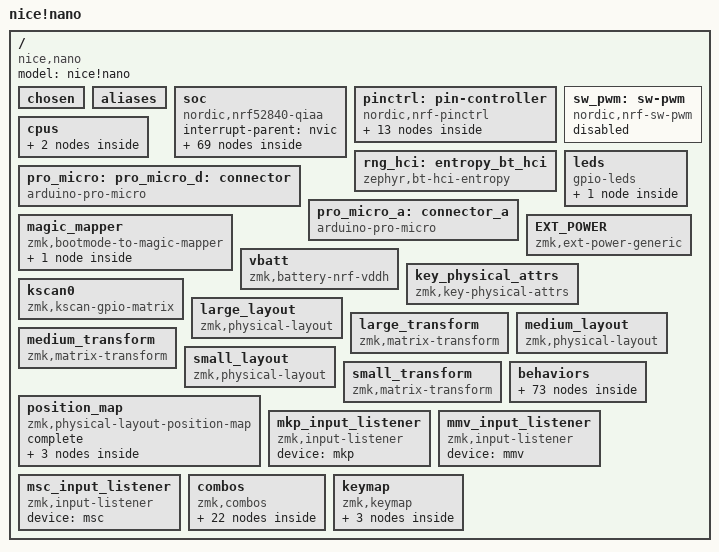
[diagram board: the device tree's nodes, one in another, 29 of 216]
/dts-v1/;

/ {
	#address-cells = < 0x1 >;
	#size-cells = < 0x1 >;
	model = "nice!nano";
	compatible = "nice,nano";
	chosen {
		zephyr,bt-hci = &bt_hci_controller;
		zephyr,entropy = &rng;
		zephyr,flash-controller = &flash_controller;
		zephyr,code-partition = &code_partition;
		zephyr,sram = &sram0;
		zephyr,flash = &flash0;
		zephyr,boot-mode = &boot_retention;
		zmk,magic-boot-mode = &adafruit_boot_retention;
		zmk,battery = &vbatt;
		zmk,kscan = &kscan0;
		zmk,physical-layout = &large_layout;
		zmk,studio-rpc-uart = &snippet_studio_rpc_usb_uart;
	};
	aliases {
	};
	soc {
		#address-cells = < 0x1 >;
		#size-cells = < 0x1 >;
		compatible = "nordic,nrf52840-qiaa", "nordic,nrf52840", "nordic,nrf52", "simple-bus";
		interrupt-parent = < &nvic >;
		ranges;
		nvic: interrupt-controller@e000e100 {
			#address-cells = < 0x1 >;
			compatible = "arm,v7m-nvic";
			reg = < 0xe000e100 0xc00 >;
			interrupt-controller;
			#interrupt-cells = < 0x2 >;
			arm,num-irq-priority-bits = < 0x3 >;
			phandle = < 0x1 >;
		};
		systick: timer@e000e010 {
			compatible = "arm,armv7m-systick";
			reg = < 0xe000e010 0x10 >;
			status = "disabled";
		};
		ficr: ficr@10000000 {
			compatible = "nordic,nrf-ficr";
			reg = < 0x10000000 0x1000 >;
			#nordic,ficr-cells = < 0x1 >;
			status = "okay";
		};
		uicr: uicr@10001000 {
			compatible = "nordic,nrf-uicr";
			reg = < 0x10001000 0x1000 >;
			status = "okay";
		};
		sram0: memory@20000000 {
			compatible = "mmio-sram";
			reg = < 0x20000000 0x40000 >;
		};
		clock: clock@40000000 {
			compatible = "nordic,nrf-clock";
			reg = < 0x40000000 0x1000 >;
			interrupts = < 0x0 0x1 >;
			status = "okay";
		};
		power: power@40000000 {
			compatible = "nordic,nrf-power";
			reg = < 0x40000000 0x1000 >;
			interrupts = < 0x0 0x1 >;
			status = "okay";
			#address-cells = < 0x1 >;
			#size-cells = < 0x1 >;
			gpregret1: gpregret1@4000051c {
				#address-cells = < 0x1 >;
				#size-cells = < 0x1 >;
				compatible = "nordic,nrf-gpregret";
				reg = < 0x4000051c 0x1 >;
				status = "okay";
				adafruit_boot_retention: retention@0 {
					compatible = "zephyr,retention";
					status = "okay";
					reg = < 0x0 0x1 >;
				};
			};
			gpregret2: gpregret2@40000520 {
				#address-cells = < 0x1 >;
				#size-cells = < 0x1 >;
				compatible = "nordic,nrf-gpregret";
				reg = < 0x40000520 0x1 >;
				status = "okay";
			};
			reg1: regulator@40000578 {
				compatible = "nordic,nrf5x-regulator";
				reg = < 0x40000578 0x1 >;
				regulator-name = "REG1";
				regulator-initial-mode = < 0x1 >;
			};
			reg0: regulator@40000580 {
				compatible = "nordic,nrf52x-regulator-hv";
				reg = < 0x40000580 0x1 >;
				regulator-name = "REG0";
				status = "okay";
			};
		};
		radio: radio@40001000 {
			compatible = "nordic,nrf-radio";
			reg = < 0x40001000 0x1000 >;
			interrupts = < 0x1 0x1 >;
			status = "okay";
			ieee802154-supported;
			ble-2mbps-supported;
			ble-coded-phy-supported;
			tx-high-power-supported;
			ieee802154: ieee802154 {
				compatible = "nordic,nrf-ieee802154";
				status = "disabled";
			};
			bt_hci_controller: bt_hci_controller {
				compatible = "zephyr,bt-hci-ll-sw-split";
				status = "okay";
			};
		};
		uart0: pro_micro_serial: uart@40002000 {
			compatible = "nordic,nrf-uarte";
			reg = < 0x40002000 0x1000 >;
			interrupts = < 0x2 0x1 >;
			status = "disabled";
			current-speed = < 0x1c200 >;
			pinctrl-0 = < &uart0_default >;
			pinctrl-1 = < &uart0_sleep >;
			pinctrl-names = "default", "sleep";
		};
		i2c0: pro_micro_i2c: i2c@40003000 {
			compatible = "nordic,nrf-twi";
			#address-cells = < 0x1 >;
			#size-cells = < 0x0 >;
			reg = < 0x40003000 0x1000 >;
			interrupts = < 0x3 0x1 >;
			easydma-maxcnt-bits = < 0x10 >;
			status = "disabled";
			zephyr,pm-device-runtime-auto;
			pinctrl-0 = < &i2c0_default >;
			pinctrl-1 = < &i2c0_sleep >;
			pinctrl-names = "default", "sleep";
		};
		spi0: spi@40003000 {
			compatible = "nordic,nrf-spim";
			#address-cells = < 0x1 >;
			#size-cells = < 0x0 >;
			reg = < 0x40003000 0x1000 >;
			interrupts = < 0x3 0x1 >;
			max-frequency = < 0x7a1200 >;
			easydma-maxcnt-bits = < 0x10 >;
			status = "disabled";
		};
		i2c1: i2c@40004000 {
			compatible = "nordic,nrf-twim";
			#address-cells = < 0x1 >;
			#size-cells = < 0x0 >;
			reg = < 0x40004000 0x1000 >;
			interrupts = < 0x4 0x1 >;
			easydma-maxcnt-bits = < 0x10 >;
			status = "disabled";
			zephyr,pm-device-runtime-auto;
		};
		spi1: pro_micro_spi: spi@40004000 {
			compatible = "nordic,nrf-spim";
			#address-cells = < 0x1 >;
			#size-cells = < 0x0 >;
			reg = < 0x40004000 0x1000 >;
			interrupts = < 0x4 0x1 >;
			max-frequency = < 0x7a1200 >;
			easydma-maxcnt-bits = < 0x10 >;
			status = "disabled";
			pinctrl-0 = < &spi1_default >;
			pinctrl-1 = < &spi1_sleep >;
			pinctrl-names = "default", "sleep";
		};
		nfct: nfct@40005000 {
			compatible = "nordic,nrf-nfct";
			reg = < 0x40005000 0x1000 >;
			interrupts = < 0x5 0x1 >;
			status = "disabled";
		};
		gpiote: gpiote0: gpiote@40006000 {
			compatible = "nordic,nrf-gpiote";
			reg = < 0x40006000 0x1000 >;
			interrupts = < 0x6 0x5 >;
			status = "okay";
			instance = < 0x0 >;
			phandle = < 0x8 >;
		};
		adc: adc@40007000 {
			compatible = "nordic,nrf-saadc";
			reg = < 0x40007000 0x1000 >;
			interrupts = < 0x7 0x1 >;
			status = "okay";
			#io-channel-cells = < 0x1 >;
			zephyr,pm-device-runtime-auto;
		};
		timer0: timer@40008000 {
			compatible = "nordic,nrf-timer";
			status = "disabled";
			reg = < 0x40008000 0x1000 >;
			cc-num = < 0x4 >;
			max-bit-width = < 0x20 >;
			interrupts = < 0x8 0x1 >;
			prescaler = < 0x0 >;
		};
		timer1: timer@40009000 {
			compatible = "nordic,nrf-timer";
			status = "disabled";
			reg = < 0x40009000 0x1000 >;
			cc-num = < 0x4 >;
			max-bit-width = < 0x20 >;
			interrupts = < 0x9 0x1 >;
			prescaler = < 0x0 >;
			phandle = < 0x9 >;
		};
		timer2: timer@4000a000 {
			compatible = "nordic,nrf-timer";
			status = "disabled";
			reg = < 0x4000a000 0x1000 >;
			cc-num = < 0x4 >;
			max-bit-width = < 0x20 >;
			interrupts = < 0xa 0x1 >;
			prescaler = < 0x0 >;
		};
		rtc0: rtc@4000b000 {
			compatible = "nordic,nrf-rtc";
			reg = < 0x4000b000 0x1000 >;
			cc-num = < 0x3 >;
			interrupts = < 0xb 0x1 >;
			status = "disabled";
			clock-frequency = < 0x8000 >;
			prescaler = < 0x1 >;
		};
		temp: temp@4000c000 {
			compatible = "nordic,nrf-temp";
			reg = < 0x4000c000 0x1000 >;
			interrupts = < 0xc 0x1 >;
			status = "okay";
		};
		rng: random@4000d000 {
			compatible = "nordic,nrf-rng";
			reg = < 0x4000d000 0x1000 >;
			interrupts = < 0xd 0x1 >;
			status = "okay";
		};
		ecb: ecb@4000e000 {
			compatible = "nordic,nrf-ecb";
			reg = < 0x4000e000 0x1000 >;
			interrupts = < 0xe 0x1 >;
			status = "okay";
		};
		ccm: ccm@4000f000 {
			compatible = "nordic,nrf-ccm";
			reg = < 0x4000f000 0x1000 >;
			interrupts = < 0xf 0x1 >;
			length-field-length-8-bits;
			status = "okay";
		};
		wdt: wdt0: watchdog@40010000 {
			compatible = "nordic,nrf-wdt";
			reg = < 0x40010000 0x1000 >;
			interrupts = < 0x10 0x1 >;
			status = "okay";
		};
		rtc1: rtc@40011000 {
			compatible = "nordic,nrf-rtc";
			reg = < 0x40011000 0x1000 >;
			cc-num = < 0x4 >;
			interrupts = < 0x11 0x1 >;
			status = "disabled";
			clock-frequency = < 0x8000 >;
			prescaler = < 0x1 >;
		};
		qdec: qdec0: qdec@40012000 {
			compatible = "nordic,nrf-qdec";
			reg = < 0x40012000 0x1000 >;
			interrupts = < 0x12 0x1 >;
			status = "disabled";
		};
		comp: comparator@40013000 {
			compatible = "nordic,nrf-comp";
			reg = < 0x40013000 0x1000 >;
			interrupts = < 0x13 0x1 >;
			status = "disabled";
		};
		egu0: swi0: egu@40014000 {
			compatible = "nordic,nrf-egu", "nordic,nrf-swi";
			reg = < 0x40014000 0x1000 >;
			interrupts = < 0x14 0x1 >;
			status = "okay";
		};
		egu1: swi1: egu@40015000 {
			compatible = "nordic,nrf-egu", "nordic,nrf-swi";
			reg = < 0x40015000 0x1000 >;
			interrupts = < 0x15 0x1 >;
			status = "okay";
		};
		egu2: swi2: egu@40016000 {
			compatible = "nordic,nrf-egu", "nordic,nrf-swi";
			reg = < 0x40016000 0x1000 >;
			interrupts = < 0x16 0x1 >;
			status = "okay";
		};
		egu3: swi3: egu@40017000 {
			compatible = "nordic,nrf-egu", "nordic,nrf-swi";
			reg = < 0x40017000 0x1000 >;
			interrupts = < 0x17 0x1 >;
			status = "okay";
		};
		egu4: swi4: egu@40018000 {
			compatible = "nordic,nrf-egu", "nordic,nrf-swi";
			reg = < 0x40018000 0x1000 >;
			interrupts = < 0x18 0x1 >;
			status = "okay";
		};
		egu5: swi5: egu@40019000 {
			compatible = "nordic,nrf-egu", "nordic,nrf-swi";
			reg = < 0x40019000 0x1000 >;
			interrupts = < 0x19 0x1 >;
			status = "okay";
		};
		timer3: timer@4001a000 {
			compatible = "nordic,nrf-timer";
			status = "disabled";
			reg = < 0x4001a000 0x1000 >;
			cc-num = < 0x6 >;
			max-bit-width = < 0x20 >;
			interrupts = < 0x1a 0x1 >;
			prescaler = < 0x0 >;
		};
		timer4: timer@4001b000 {
			compatible = "nordic,nrf-timer";
			status = "disabled";
			reg = < 0x4001b000 0x1000 >;
			cc-num = < 0x6 >;
			max-bit-width = < 0x20 >;
			interrupts = < 0x1b 0x1 >;
			prescaler = < 0x0 >;
		};
		pwm0: pwm@4001c000 {
			compatible = "nordic,nrf-pwm";
			reg = < 0x4001c000 0x1000 >;
			interrupts = < 0x1c 0x1 >;
			status = "disabled";
			#pwm-cells = < 0x3 >;
		};
		pdm0: pdm@4001d000 {
			compatible = "nordic,nrf-pdm";
			reg = < 0x4001d000 0x1000 >;
			interrupts = < 0x1d 0x1 >;
			status = "disabled";
		};
		acl: acl@4001e000 {
			compatible = "nordic,nrf-acl";
			reg = < 0x4001e000 0x1000 >;
			status = "okay";
		};
		flash_controller: flash-controller@4001e000 {
			compatible = "nordic,nrf52-flash-controller";
			reg = < 0x4001e000 0x1000 >;
			partial-erase;
			#address-cells = < 0x1 >;
			#size-cells = < 0x1 >;
			flash0: flash@0 {
				compatible = "soc-nv-flash";
				erase-block-size = < 0x1000 >;
				write-block-size = < 0x4 >;
				reg = < 0x0 0x100000 >;
				partitions {
					compatible = "fixed-partitions";
					#address-cells = < 0x1 >;
					#size-cells = < 0x1 >;
					sd_partition: partition@0 {
						reg = < 0x0 0x26000 >;
					};
					code_partition: partition@26000 {
						reg = < 0x26000 0xc6000 >;
					};
					storage_partition: partition@ec000 {
						reg = < 0xec000 0x8000 >;
					};
					boot_partition: partition@f4000 {
						reg = < 0xf4000 0xc000 >;
					};
				};
			};
		};
		ppi: ppi@4001f000 {
			compatible = "nordic,nrf-ppi";
			reg = < 0x4001f000 0x1000 >;
			status = "okay";
		};
		mwu: mwu@40020000 {
			compatible = "nordic,nrf-mwu";
			reg = < 0x40020000 0x1000 >;
			status = "okay";
		};
		pwm1: pwm@40021000 {
			compatible = "nordic,nrf-pwm";
			reg = < 0x40021000 0x1000 >;
			interrupts = < 0x21 0x1 >;
			status = "disabled";
			#pwm-cells = < 0x3 >;
		};
		pwm2: pwm@40022000 {
			compatible = "nordic,nrf-pwm";
			reg = < 0x40022000 0x1000 >;
			interrupts = < 0x22 0x1 >;
			status = "disabled";
			#pwm-cells = < 0x3 >;
		};
		spi2: spi@40023000 {
			compatible = "nordic,nrf-spim";
			#address-cells = < 0x1 >;
			#size-cells = < 0x0 >;
			reg = < 0x40023000 0x1000 >;
			interrupts = < 0x23 0x1 >;
			max-frequency = < 0x7a1200 >;
			easydma-maxcnt-bits = < 0x10 >;
			status = "disabled";
		};
		rtc2: rtc@40024000 {
			compatible = "nordic,nrf-rtc";
			reg = < 0x40024000 0x1000 >;
			cc-num = < 0x4 >;
			interrupts = < 0x24 0x1 >;
			status = "disabled";
			clock-frequency = < 0x8000 >;
			prescaler = < 0x1 >;
		};
		i2s0: i2s@40025000 {
			compatible = "nordic,nrf-i2s";
			#address-cells = < 0x1 >;
			#size-cells = < 0x0 >;
			reg = < 0x40025000 0x1000 >;
			interrupts = < 0x25 0x1 >;
			status = "disabled";
		};
		usbd: zephyr_udc0: usbd@40027000 {
			compatible = "nordic,nrf-usbd";
			reg = < 0x40027000 0x1000 >;
			interrupts = < 0x27 0x1 >;
			num-bidir-endpoints = < 0x1 >;
			num-in-endpoints = < 0x7 >;
			num-out-endpoints = < 0x7 >;
			num-isoin-endpoints = < 0x1 >;
			num-isoout-endpoints = < 0x1 >;
			status = "okay";
			snippet_studio_rpc_usb_uart: snippet_studio_rpc_usb_uart {
				compatible = "zephyr,cdc-acm-uart";
			};
		};
		uart1: uart@40028000 {
			compatible = "nordic,nrf-uarte";
			reg = < 0x40028000 0x1000 >;
			interrupts = < 0x28 0x1 >;
			status = "disabled";
		};
		qspi: qspi@40029000 {
			compatible = "nordic,nrf-qspi";
			#address-cells = < 0x1 >;
			#size-cells = < 0x0 >;
			reg = < 0x40029000 0x1000 >, < 0x12000000 0x8000000 >;
			reg-names = "qspi", "qspi_mm";
			interrupts = < 0x29 0x1 >;
			status = "disabled";
		};
		pwm3: pwm@4002d000 {
			compatible = "nordic,nrf-pwm";
			reg = < 0x4002d000 0x1000 >;
			interrupts = < 0x2d 0x1 >;
			status = "disabled";
			#pwm-cells = < 0x3 >;
		};
		spi3: spi@4002f000 {
			compatible = "nordic,nrf-spim";
			#address-cells = < 0x1 >;
			#size-cells = < 0x0 >;
			reg = < 0x4002f000 0x1000 >;
			interrupts = < 0x2f 0x1 >;
			max-frequency = < 0x1e84800 >;
			easydma-maxcnt-bits = < 0x10 >;
			rx-delay-supported;
			rx-delay = < 0x2 >;
			status = "disabled";
		};
		gpio0: gpio@50000000 {
			compatible = "nordic,nrf-gpio";
			gpio-controller;
			reg = < 0x50000000 0x200 0x50000500 0x300 >;
			#gpio-cells = < 0x2 >;
			status = "okay";
			port = < 0x0 >;
			gpiote-instance = < &gpiote >;
			phandle = < 0xa >;
		};
		gpio1: gpio@50000300 {
			compatible = "nordic,nrf-gpio";
			gpio-controller;
			reg = < 0x50000300 0x200 0x50000800 0x300 >;
			#gpio-cells = < 0x2 >;
			ngpios = < 0x10 >;
			status = "okay";
			port = < 0x1 >;
			gpiote-instance = < &gpiote >;
			phandle = < 0xb >;
		};
		cryptocell: crypto@5002a000 {
			compatible = "nordic,cryptocell", "arm,cryptocell-310";
			reg = < 0x5002a000 0x1000 >, < 0x5002b000 0x1000 >;
			reg-names = "wrapper", "core";
			interrupts = < 0x2a 0x1 >;
			status = "disabled";
		};
	};
	pinctrl: pin-controller {
		compatible = "nordic,nrf-pinctrl";
		uart0_default: uart0_default {
			phandle = < 0x2 >;
			group1 {
				psels = < 0x1000008 >;
				bias-pull-up;
			};
			group2 {
				psels = < 0x6 >;
			};
		};
		uart0_sleep: uart0_sleep {
			phandle = < 0x3 >;
			group1 {
				psels = < 0x1000008 >, < 0x6 >;
				low-power-enable;
			};
		};
		i2c0_default: i2c0_default {
			phandle = < 0x4 >;
			group1 {
				psels = < 0xc000011 >, < 0xb000014 >;
			};
		};
		i2c0_sleep: i2c0_sleep {
			phandle = < 0x5 >;
			group1 {
				psels = < 0xc000011 >, < 0xb000014 >;
				low-power-enable;
			};
		};
		spi1_default: spi1_default {
			phandle = < 0x6 >;
			group1 {
				psels = < 0x400002d >, < 0x500000a >, < 0x600002b >;
			};
		};
		spi1_sleep: spi1_sleep {
			phandle = < 0x7 >;
			group1 {
				psels = < 0x400002d >, < 0x500000a >, < 0x600002b >;
				low-power-enable;
			};
		};
	};
	rng_hci: entropy_bt_hci {
		compatible = "zephyr,bt-hci-entropy";
		status = "okay";
	};
	sw_pwm: sw-pwm {
		compatible = "nordic,nrf-sw-pwm";
		status = "disabled";
		generator = < &timer1 >;
		clock-prescaler = < 0x0 >;
		#pwm-cells = < 0x3 >;
	};
	cpus {
		#address-cells = < 0x1 >;
		#size-cells = < 0x0 >;
		cpu@0 {
			device_type = "cpu";
			compatible = "arm,cortex-m4f";
			reg = < 0x0 >;
			#address-cells = < 0x1 >;
			#size-cells = < 0x1 >;
			itm: itm@e0000000 {
				compatible = "arm,armv7m-itm";
				reg = < 0xe0000000 0x1000 >;
				swo-ref-frequency = < 0x1e84800 >;
			};
		};
	};
	pro_micro: pro_micro_d: connector {
		compatible = "arduino-pro-micro";
		#gpio-cells = < 0x2 >;
		gpio-map-mask = < 0xffffffff 0xffffffc0 >;
		gpio-map-pass-thru = < 0x0 0x3f >;
		gpio-map = < 0x0 0x0 &gpio0 0x8 0x0 >, < 0x1 0x0 &gpio0 0x6 0x0 >, < 0x2 0x0 &gpio0 0x11 0x0 >, < 0x3 0x0 &gpio0 0x14 0x0 >, < 0x4 0x0 &gpio0 0x16 0x0 >, < 0x5 0x0 &gpio0 0x18 0x0 >, < 0x6 0x0 &gpio1 0x0 0x0 >, < 0x7 0x0 &gpio0 0xb 0x0 >, < 0x8 0x0 &gpio1 0x4 0x0 >, < 0x9 0x0 &gpio1 0x6 0x0 >, < 0xa 0x0 &gpio0 0x9 0x0 >, < 0x10 0x0 &gpio0 0xa 0x0 >, < 0xe 0x0 &gpio1 0xb 0x0 >, < 0xf 0x0 &gpio1 0xd 0x0 >, < 0x12 0x0 &gpio1 0xf 0x0 >, < 0x13 0x0 &gpio0 0x2 0x0 >, < 0x14 0x0 &gpio0 0x1d 0x0 >, < 0x15 0x0 &gpio0 0x1f 0x0 >;
		phandle = < 0xc >;
	};
	pro_micro_a: connector_a {
		compatible = "arduino-pro-micro";
		#gpio-cells = < 0x2 >;
		gpio-map-mask = < 0xffffffff 0xffffffc0 >;
		gpio-map-pass-thru = < 0x0 0x3f >;
		gpio-map = < 0x0 0x0 &gpio1 0xf 0x0 >, < 0x1 0x0 &gpio0 0x2 0x0 >, < 0x2 0x0 &gpio0 0x1d 0x0 >, < 0x3 0x0 &gpio0 0x1f 0x0 >, < 0x6 0x0 &gpio0 0x16 0x0 >, < 0x7 0x0 &gpio1 0x0 0x0 >, < 0x8 0x0 &gpio1 0x4 0x0 >, < 0x9 0x0 &gpio1 0x6 0x0 >, < 0xa 0x0 &gpio0 0x9 0x0 >;
	};
	leds {
		compatible = "gpio-leds";
		blue_led: led_0 {
			gpios = < &gpio0 0xf 0x0 >;
		};
	};
	magic_mapper {
		compatible = "zmk,bootmode-to-magic-mapper";
		status = "okay";
		#address-cells = < 0x1 >;
		#size-cells = < 0x1 >;
		boot_retention: retention@0 {
			compatible = "zephyr,retention";
			status = "okay";
			reg = < 0x0 0x1 >;
		};
	};
	EXT_POWER {
		compatible = "zmk,ext-power-generic";
		control-gpios = < &gpio0 0xd 0x0 >;
		init-delay-ms = < 0x32 >;
	};
	vbatt: vbatt {
		compatible = "zmk,battery-nrf-vddh";
	};
	key_physical_attrs: key_physical_attrs {
		compatible = "zmk,key-physical-attrs";
		#key-cells = < 0x7 >;
		phandle = < 0xe >;
	};
	kscan0: kscan0 {
		compatible = "zmk,kscan-gpio-matrix";
		diode-direction = "col2row";
		wakeup-source;
		col-gpios = < &pro_micro 0x2 0x0 >, < &pro_micro 0x3 0x0 >, < &pro_micro 0x4 0x0 >, < &pro_micro 0x5 0x0 >, < &pro_micro 0x6 0x0 >, < &pro_micro 0x7 0x0 >;
		row-gpios = < &pro_micro 0x8 0x20 >, < &pro_micro 0x9 0x20 >, < &pro_micro 0xa 0x20 >, < &pro_micro 0x10 0x20 >, < &pro_micro 0xe 0x20 >;
	};
	large_layout: large_layout {
		compatible = "zmk,physical-layout";
		display-name = "Flake L Layout";
		transform = < &large_transform >;
		keys = < &key_physical_attrs 0x64 0x64 0x0 0x4b 0x0 0x0 0x0 >, < &key_physical_attrs 0x64 0x64 0x64 0x4b 0x0 0x0 0x0 >, < &key_physical_attrs 0x64 0x64 0xc8 0x19 0x0 0x0 0x0 >, < &key_physical_attrs 0x64 0x64 0x12c 0x0 0x0 0x0 0x0 >, < &key_physical_attrs 0x64 0x64 0x190 0x19 0x0 0x0 0x0 >, < &key_physical_attrs 0x64 0x64 0x1f4 0x19 0x0 0x0 0x0 >, < &key_physical_attrs 0x64 0x64 0x3e8 0x19 0x0 0x0 0x0 >, < &key_physical_attrs 0x64 0x64 0x44c 0x19 0x0 0x0 0x0 >, < &key_physical_attrs 0x64 0x64 0x4b0 0x0 0x0 0x0 0x0 >, < &key_physical_attrs 0x64 0x64 0x514 0x19 0x0 0x0 0x0 >, < &key_physical_attrs 0x64 0x64 0x578 0x4b 0x0 0x0 0x0 >, < &key_physical_attrs 0x64 0x64 0x5dc 0x4b 0x0 0x0 0x0 >, < &key_physical_attrs 0x64 0x64 0x0 0xaf 0x0 0x0 0x0 >, < &key_physical_attrs 0x64 0x64 0x64 0xaf 0x0 0x0 0x0 >, < &key_physical_attrs 0x64 0x64 0xc8 0x7d 0x0 0x0 0x0 >, < &key_physical_attrs 0x64 0x64 0x12c 0x64 0x0 0x0 0x0 >, < &key_physical_attrs 0x64 0x64 0x190 0x7d 0x0 0x0 0x0 >, < &key_physical_attrs 0x64 0x64 0x1f4 0x7d 0x0 0x0 0x0 >, < &key_physical_attrs 0x64 0x64 0x3e8 0x7d 0x0 0x0 0x0 >, < &key_physical_attrs 0x64 0x64 0x44c 0x7d 0x0 0x0 0x0 >, < &key_physical_attrs 0x64 0x64 0x4b0 0x64 0x0 0x0 0x0 >, < &key_physical_attrs 0x64 0x64 0x514 0x7d 0x0 0x0 0x0 >, < &key_physical_attrs 0x64 0x64 0x578 0xaf 0x0 0x0 0x0 >, < &key_physical_attrs 0x64 0x64 0x5dc 0xaf 0x0 0x0 0x0 >, < &key_physical_attrs 0x64 0x64 0x0 0x113 0x0 0x0 0x0 >, < &key_physical_attrs 0x64 0x64 0x64 0x113 0x0 0x0 0x0 >, < &key_physical_attrs 0x64 0x64 0xc8 0xe1 0x0 0x0 0x0 >, < &key_physical_attrs 0x64 0x64 0x12c 0xc8 0x0 0x0 0x0 >, < &key_physical_attrs 0x64 0x64 0x190 0xe1 0x0 0x0 0x0 >, < &key_physical_attrs 0x64 0x64 0x1f4 0xe1 0x0 0x0 0x0 >, < &key_physical_attrs 0x64 0x64 0x3e8 0xe1 0x0 0x0 0x0 >, < &key_physical_attrs 0x64 0x64 0x44c 0xe1 0x0 0x0 0x0 >, < &key_physical_attrs 0x64 0x64 0x4b0 0xc8 0x0 0x0 0x0 >, < &key_physical_attrs 0x64 0x64 0x514 0xe1 0x0 0x0 0x0 >, < &key_physical_attrs 0x64 0x64 0x578 0x113 0x0 0x0 0x0 >, < &key_physical_attrs 0x64 0x64 0x5dc 0x113 0x0 0x0 0x0 >, < &key_physical_attrs 0x64 0x64 0x0 0x177 0x0 0x0 0x0 >, < &key_physical_attrs 0x64 0x64 0x64 0x177 0x0 0x0 0x0 >, < &key_physical_attrs 0x64 0x64 0xc8 0x145 0x0 0x0 0x0 >, < &key_physical_attrs 0x64 0x64 0x12c 0x12c 0x0 0x0 0x0 >, < &key_physical_attrs 0x64 0x64 0x190 0x145 0x0 0x0 0x0 >, < &key_physical_attrs 0x64 0x64 0x1f4 0x145 0x0 0x0 0x0 >, < &key_physical_attrs 0x64 0x64 0x3e8 0x145 0x0 0x0 0x0 >, < &key_physical_attrs 0x64 0x64 0x44c 0x145 0x0 0x0 0x0 >, < &key_physical_attrs 0x64 0x64 0x4b0 0x12c 0x0 0x0 0x0 >, < &key_physical_attrs 0x64 0x64 0x514 0x145 0x0 0x0 0x0 >, < &key_physical_attrs 0x64 0x64 0x578 0x177 0x0 0x0 0x0 >, < &key_physical_attrs 0x64 0x64 0x5dc 0x177 0x0 0x0 0x0 >, < &key_physical_attrs 0x64 0x64 0xc8 0x1a9 0x0 0x0 0x0 >, < &key_physical_attrs 0x64 0x64 0x12c 0x190 0x0 0x0 0x0 >, < &key_physical_attrs 0x64 0x64 0x190 0x1a9 0x0 0x0 0x0 >, < &key_physical_attrs 0x64 0x64 0x1f4 0x1a9 0x5dc 0x1f4 0x20d >, < &key_physical_attrs 0x64 0x64 0x258 0x1d6 0xbb8 0x276 0x230 >, < &key_physical_attrs 0x64 0x64 0x384 0x1d6 0xfffff448 0x3ca 0x230 >, < &key_physical_attrs 0x64 0x64 0x3e8 0x1a9 0xfffffa24 0x44c 0x20d >, < &key_physical_attrs 0x64 0x64 0x44c 0x1a9 0x0 0x0 0x0 >, < &key_physical_attrs 0x64 0x64 0x4b0 0x190 0x0 0x0 0x0 >, < &key_physical_attrs 0x64 0x64 0x514 0x1a9 0x0 0x0 0x0 >;
		phandle = < 0x11 >;
	};
	large_transform: large_transform {
		compatible = "zmk,matrix-transform";
		columns = < 0xc >;
		rows = < 0x5 >;
		map = < 0x0 0x1 0x2 0x3 0x4 0x5 0x6 0x7 0x8 0x9 0xa 0xb 0x100 0x101 0x102 0x103 0x104 0x105 0x106 0x107 0x108 0x109 0x10a 0x10b 0x200 0x201 0x202 0x203 0x204 0x205 0x206 0x207 0x208 0x209 0x20a 0x20b 0x300 0x301 0x302 0x303 0x304 0x305 0x306 0x307 0x308 0x309 0x30a 0x30b 0x401 0x402 0x403 0x404 0x405 0x406 0x407 0x408 0x409 0x40a >;
		phandle = < 0xd >;
	};
	medium_layout: medium_layout {
		compatible = "zmk,physical-layout";
		display-name = "Flake M Layout";
		transform = < &medium_transform >;
		keys = < &key_physical_attrs 0x64 0x64 0x0 0x4b 0x0 0x0 0x0 >, < &key_physical_attrs 0x64 0x64 0x64 0x4b 0x0 0x0 0x0 >, < &key_physical_attrs 0x64 0x64 0xc8 0x19 0x0 0x0 0x0 >, < &key_physical_attrs 0x64 0x64 0x12c 0x0 0x0 0x0 0x0 >, < &key_physical_attrs 0x64 0x64 0x190 0x19 0x0 0x0 0x0 >, < &key_physical_attrs 0x64 0x64 0x1f4 0x19 0x0 0x0 0x0 >, < &key_physical_attrs 0x64 0x64 0x3e8 0x19 0x0 0x0 0x0 >, < &key_physical_attrs 0x64 0x64 0x44c 0x19 0x0 0x0 0x0 >, < &key_physical_attrs 0x64 0x64 0x4b0 0x0 0x0 0x0 0x0 >, < &key_physical_attrs 0x64 0x64 0x514 0x19 0x0 0x0 0x0 >, < &key_physical_attrs 0x64 0x64 0x578 0x4b 0x0 0x0 0x0 >, < &key_physical_attrs 0x64 0x64 0x5dc 0x4b 0x0 0x0 0x0 >, < &key_physical_attrs 0x64 0x64 0x0 0xaf 0x0 0x0 0x0 >, < &key_physical_attrs 0x64 0x64 0x64 0xaf 0x0 0x0 0x0 >, < &key_physical_attrs 0x64 0x64 0xc8 0x7d 0x0 0x0 0x0 >, < &key_physical_attrs 0x64 0x64 0x12c 0x64 0x0 0x0 0x0 >, < &key_physical_attrs 0x64 0x64 0x190 0x7d 0x0 0x0 0x0 >, < &key_physical_attrs 0x64 0x64 0x1f4 0x7d 0x0 0x0 0x0 >, < &key_physical_attrs 0x64 0x64 0x3e8 0x7d 0x0 0x0 0x0 >, < &key_physical_attrs 0x64 0x64 0x44c 0x7d 0x0 0x0 0x0 >, < &key_physical_attrs 0x64 0x64 0x4b0 0x64 0x0 0x0 0x0 >, < &key_physical_attrs 0x64 0x64 0x514 0x7d 0x0 0x0 0x0 >, < &key_physical_attrs 0x64 0x64 0x578 0xaf 0x0 0x0 0x0 >, < &key_physical_attrs 0x64 0x64 0x5dc 0xaf 0x0 0x0 0x0 >, < &key_physical_attrs 0x64 0x64 0x0 0x113 0x0 0x0 0x0 >, < &key_physical_attrs 0x64 0x64 0x64 0x113 0x0 0x0 0x0 >, < &key_physical_attrs 0x64 0x64 0xc8 0xe1 0x0 0x0 0x0 >, < &key_physical_attrs 0x64 0x64 0x12c 0xc8 0x0 0x0 0x0 >, < &key_physical_attrs 0x64 0x64 0x190 0xe1 0x0 0x0 0x0 >, < &key_physical_attrs 0x64 0x64 0x1f4 0xe1 0x0 0x0 0x0 >, < &key_physical_attrs 0x64 0x64 0x3e8 0xe1 0x0 0x0 0x0 >, < &key_physical_attrs 0x64 0x64 0x44c 0xe1 0x0 0x0 0x0 >, < &key_physical_attrs 0x64 0x64 0x4b0 0xc8 0x0 0x0 0x0 >, < &key_physical_attrs 0x64 0x64 0x514 0xe1 0x0 0x0 0x0 >, < &key_physical_attrs 0x64 0x64 0x578 0x113 0x0 0x0 0x0 >, < &key_physical_attrs 0x64 0x64 0x5dc 0x113 0x0 0x0 0x0 >, < &key_physical_attrs 0x64 0x64 0xc8 0x145 0x0 0x0 0x0 >, < &key_physical_attrs 0x64 0x64 0x12c 0x12c 0x0 0x0 0x0 >, < &key_physical_attrs 0x64 0x64 0x190 0x145 0x0 0x0 0x0 >, < &key_physical_attrs 0x64 0x64 0x1f4 0x145 0x5dc 0x1f4 0x1a9 >, < &key_physical_attrs 0x64 0x64 0x258 0x172 0xbb8 0x276 0x1cc >, < &key_physical_attrs 0x64 0x64 0x384 0x172 0xfffff448 0x3ca 0x1cc >, < &key_physical_attrs 0x64 0x64 0x3e8 0x145 0xfffffa24 0x44c 0x1a9 >, < &key_physical_attrs 0x64 0x64 0x44c 0x145 0x0 0x0 0x0 >, < &key_physical_attrs 0x64 0x64 0x4b0 0x12c 0x0 0x0 0x0 >, < &key_physical_attrs 0x64 0x64 0x514 0x145 0x0 0x0 0x0 >;
		phandle = < 0x12 >;
	};
	medium_transform: medium_transform {
		compatible = "zmk,matrix-transform";
		columns = < 0xc >;
		rows = < 0x4 >;
		map = < 0x100 0x101 0x102 0x103 0x104 0x105 0x106 0x107 0x108 0x109 0x10a 0x10b 0x200 0x201 0x202 0x203 0x204 0x205 0x206 0x207 0x208 0x209 0x20a 0x20b 0x300 0x301 0x302 0x303 0x304 0x305 0x306 0x307 0x308 0x309 0x30a 0x30b 0x401 0x402 0x403 0x404 0x405 0x406 0x407 0x408 0x409 0x40a >;
		phandle = < 0xf >;
	};
	small_layout: small_layout {
		compatible = "zmk,physical-layout";
		display-name = "Flake S Layout";
		transform = < &small_transform >;
		keys = < &key_physical_attrs 0x64 0x64 0x0 0x4b 0x0 0x0 0x0 >, < &key_physical_attrs 0x64 0x64 0x64 0x19 0x0 0x0 0x0 >, < &key_physical_attrs 0x64 0x64 0xc8 0x0 0x0 0x0 0x0 >, < &key_physical_attrs 0x64 0x64 0x12c 0x19 0x0 0x0 0x0 >, < &key_physical_attrs 0x64 0x64 0x190 0x19 0x0 0x0 0x0 >, < &key_physical_attrs 0x64 0x64 0x384 0x19 0x0 0x0 0x0 >, < &key_physical_attrs 0x64 0x64 0x3e8 0x19 0x0 0x0 0x0 >, < &key_physical_attrs 0x64 0x64 0x44c 0x0 0x0 0x0 0x0 >, < &key_physical_attrs 0x64 0x64 0x4b0 0x19 0x0 0x0 0x0 >, < &key_physical_attrs 0x64 0x64 0x514 0x4b 0x0 0x0 0x0 >, < &key_physical_attrs 0x64 0x64 0x0 0xaf 0x0 0x0 0x0 >, < &key_physical_attrs 0x64 0x64 0x64 0x7d 0x0 0x0 0x0 >, < &key_physical_attrs 0x64 0x64 0xc8 0x64 0x0 0x0 0x0 >, < &key_physical_attrs 0x64 0x64 0x12c 0x7d 0x0 0x0 0x0 >, < &key_physical_attrs 0x64 0x64 0x190 0x7d 0x0 0x0 0x0 >, < &key_physical_attrs 0x64 0x64 0x384 0x7d 0x0 0x0 0x0 >, < &key_physical_attrs 0x64 0x64 0x3e8 0x7d 0x0 0x0 0x0 >, < &key_physical_attrs 0x64 0x64 0x44c 0x64 0x0 0x0 0x0 >, < &key_physical_attrs 0x64 0x64 0x4b0 0x7d 0x0 0x0 0x0 >, < &key_physical_attrs 0x64 0x64 0x514 0xaf 0x0 0x0 0x0 >, < &key_physical_attrs 0x64 0x64 0x0 0x113 0x0 0x0 0x0 >, < &key_physical_attrs 0x64 0x64 0x64 0xe1 0x0 0x0 0x0 >, < &key_physical_attrs 0x64 0x64 0xc8 0xc8 0x0 0x0 0x0 >, < &key_physical_attrs 0x64 0x64 0x12c 0xe1 0x0 0x0 0x0 >, < &key_physical_attrs 0x64 0x64 0x190 0xe1 0x0 0x0 0x0 >, < &key_physical_attrs 0x64 0x64 0x384 0xe1 0x0 0x0 0x0 >, < &key_physical_attrs 0x64 0x64 0x3e8 0xe1 0x0 0x0 0x0 >, < &key_physical_attrs 0x64 0x64 0x44c 0xc8 0x0 0x0 0x0 >, < &key_physical_attrs 0x64 0x64 0x4b0 0xe1 0x0 0x0 0x0 >, < &key_physical_attrs 0x64 0x64 0x514 0x113 0x0 0x0 0x0 >, < &key_physical_attrs 0x64 0x64 0x64 0x145 0x0 0x0 0x0 >, < &key_physical_attrs 0x64 0x64 0xc8 0x12c 0x0 0x0 0x0 >, < &key_physical_attrs 0x64 0x64 0x12c 0x145 0x0 0x0 0x0 >, < &key_physical_attrs 0x64 0x64 0x190 0x145 0x5dc 0x190 0x1a9 >, < &key_physical_attrs 0x64 0x64 0x1f4 0x172 0xbb8 0x212 0x1cc >, < &key_physical_attrs 0x64 0x64 0x320 0x172 0xfffff448 0x366 0x1cc >, < &key_physical_attrs 0x64 0x64 0x384 0x145 0xfffffa24 0x3e8 0x1a9 >, < &key_physical_attrs 0x64 0x64 0x3e8 0x145 0x0 0x0 0x0 >, < &key_physical_attrs 0x64 0x64 0x44c 0x12c 0x0 0x0 0x0 >, < &key_physical_attrs 0x64 0x64 0x4b0 0x145 0x0 0x0 0x0 >;
		phandle = < 0x13 >;
	};
	small_transform: small_transform {
		compatible = "zmk,matrix-transform";
		columns = < 0xa >;
		rows = < 0x4 >;
		map = < 0x101 0x102 0x103 0x104 0x105 0x106 0x107 0x108 0x109 0x10a 0x201 0x202 0x203 0x204 0x205 0x206 0x207 0x208 0x209 0x20a 0x301 0x302 0x303 0x304 0x305 0x306 0x307 0x308 0x309 0x30a 0x401 0x402 0x403 0x404 0x405 0x406 0x407 0x408 0x409 0x40a >;
		phandle = < 0x10 >;
	};
	position_map {
		compatible = "zmk,physical-layout-position-map";
		complete;
		large_layout {
			physical-layout = < &large_layout >;
			positions = < 0x0 0x1 0x2 0x3 0x4 0x5 0x6 0x7 0x8 0x9 0xa 0xb >, < 0xc 0xd 0xe 0xf 0x10 0x11 0x12 0x13 0x14 0x15 0x16 0x17 >, < 0x18 0x19 0x1a 0x1b 0x1c 0x1d 0x1e 0x1f 0x20 0x21 0x22 0x23 >, < 0x24 0x25 0x26 0x27 0x28 0x29 0x2a 0x2b 0x2c 0x2d 0x2e 0x2f >, < 0x30 0x31 0x32 0x33 0x34 0x35 0x36 0x37 0x38 0x39 >;
		};
		medium_layout {
			physical-layout = < &medium_layout >;
			positions = < 0x2e 0x2f 0x30 0x31 0x32 0x33 0x34 0x35 0x36 0x37 0x38 0x39 >, < 0x0 0x1 0x2 0x3 0x4 0x5 0x6 0x7 0x8 0x9 0xa 0xb >, < 0xc 0xd 0xe 0xf 0x10 0x11 0x12 0x13 0x14 0x15 0x16 0x17 >, < 0x18 0x19 0x1a 0x1b 0x1c 0x1d 0x1e 0x1f 0x20 0x21 0x22 0x23 >, < 0x24 0x25 0x26 0x27 0x28 0x29 0x2a 0x2b 0x2c 0x2d >;
		};
		small_layout {
			physical-layout = < &small_layout >;
			positions = < 0x28 0x29 0x2a 0x2b 0x2c 0x2d 0x2e 0x2f 0x30 0x31 0x32 0x33 >, < 0x34 0x0 0x1 0x2 0x3 0x4 0x5 0x6 0x7 0x8 0x9 0x35 >, < 0x36 0xa 0xb 0xc 0xd 0xe 0xf 0x10 0x11 0x12 0x13 0x37 >, < 0x38 0x14 0x15 0x16 0x17 0x18 0x19 0x1a 0x1b 0x1c 0x1d 0x39 >, < 0x1e 0x1f 0x20 0x21 0x22 0x23 0x24 0x25 0x26 0x27 >;
		};
	};
	behaviors {
		kp: key_press {
			compatible = "zmk,behavior-key-press";
			#binding-cells = < 0x1 >;
			display-name = "Key Press";
			phandle = < 0x14 >;
		};
		kt: key_toggle {
			compatible = "zmk,behavior-key-toggle";
			#binding-cells = < 0x1 >;
			display-name = "Key Toggle";
			phandle = < 0x20 >;
		};
		trans: transparent {
			compatible = "zmk,behavior-transparent";
			#binding-cells = < 0x0 >;
			display-name = "Transparent";
			phandle = < 0x38 >;
		};
		none: none {
			compatible = "zmk,behavior-none";
			#binding-cells = < 0x0 >;
			display-name = "None";
			phandle = < 0x36 >;
		};
		mt: mod_tap {
			compatible = "zmk,behavior-hold-tap";
			#binding-cells = < 0x2 >;
			flavor = "tap-preferred";
			tapping-term-ms = < 0xdc >;
			bindings = < &kp >, < &kp >;
			display-name = "Mod-Tap";
			quick-tap-ms = < 0xdc >;
			hold-trigger-key-positions = < 0x0 >;
			phandle = < 0x3a >;
		};
		lt: layer_tap {
			compatible = "zmk,behavior-hold-tap";
			#binding-cells = < 0x2 >;
			flavor = "balanced";
			tapping-term-ms = < 0xc8 >;
			bindings = < &mo >, < &kp >;
			display-name = "Layer-Tap";
			quick-tap-ms = < 0xaf >;
			phandle = < 0x32 >;
		};
		gresc: grave_escape {
			compatible = "zmk,behavior-mod-morph";
			#binding-cells = < 0x0 >;
			bindings = < &kp 0x70029 >, < &kp 0x70035 >;
			mods = < 0xaa >;
			display-name = "Grave/Escape";
		};
		sk: sticky_key {
			compatible = "zmk,behavior-sticky-key";
			#binding-cells = < 0x1 >;
			release-after-ms = < 0x384 >;
			bindings = < &kp >;
			ignore-modifiers;
			display-name = "Sticky Key";
			quick-release;
			phandle = < 0x25 >;
		};
		sl: sticky_layer {
			compatible = "zmk,behavior-sticky-key";
			#binding-cells = < 0x1 >;
			release-after-ms = < 0x3e8 >;
			bindings = < &mo >;
			quick-release;
			display-name = "Sticky Layer";
			ignore-modifiers;
		};
		mo: momentary_layer {
			compatible = "zmk,behavior-momentary-layer";
			#binding-cells = < 0x1 >;
			display-name = "Momentary Layer";
			phandle = < 0x15 >;
		};
		tog: toggle_layer {
			compatible = "zmk,behavior-toggle-layer";
			#binding-cells = < 0x1 >;
			display-name = "Toggle Layer";
			locking;
		};
		to: to_layer {
			compatible = "zmk,behavior-to-layer";
			#binding-cells = < 0x1 >;
			display-name = "To Layer";
			locking;
		};
		sys_reset: sysreset {
			compatible = "zmk,behavior-reset";
			#binding-cells = < 0x0 >;
			display-name = "Reset";
		};
		bootloader: bootload {
			compatible = "zmk,behavior-reset";
			type = < 0x57 >;
			bootloader;
			#binding-cells = < 0x0 >;
			display-name = "Bootloader";
		};
		rgb_ug: rgb_ug {
			compatible = "zmk,behavior-rgb-underglow";
			#binding-cells = < 0x2 >;
			display-name = "Underglow";
		};
		bt: bluetooth {
			compatible = "zmk,behavior-bluetooth";
			#binding-cells = < 0x2 >;
			display-name = "Bluetooth";
		};
		ext_power: extpower {
			compatible = "zmk,behavior-ext-power";
			#binding-cells = < 0x1 >;
			display-name = "External Power";
		};
		out: outputs {
			compatible = "zmk,behavior-outputs";
			#binding-cells = < 0x1 >;
			display-name = "Output Selection";
		};
		caps_word: caps_word {
			compatible = "zmk,behavior-caps-word";
			#binding-cells = < 0x0 >;
			continue-list = < 0x207002d 0x7002a 0x7004c >;
			display-name = "Caps Word";
			phandle = < 0x29 >;
		};
		key_repeat: key_repeat {
			compatible = "zmk,behavior-key-repeat";
			#binding-cells = < 0x0 >;
			usage-pages = < 0x7 >;
			display-name = "Key Repeat";
		};
		bl: bcklight {
			compatible = "zmk,behavior-backlight";
			#binding-cells = < 0x2 >;
			display-name = "Backlight";
		};
		macro_tap: macro_tap {
			compatible = "zmk,macro-control-mode-tap";
			#binding-cells = < 0x0 >;
		};
		macro_press: macro_press {
			compatible = "zmk,macro-control-mode-press";
			#binding-cells = < 0x0 >;
		};
		macro_release: macro_release {
			compatible = "zmk,macro-control-mode-release";
			#binding-cells = < 0x0 >;
		};
		macro_tap_time: macro_tap_time {
			compatible = "zmk,macro-control-tap-time";
			#binding-cells = < 0x1 >;
		};
		macro_wait_time: macro_wait_time {
			compatible = "zmk,macro-control-wait-time";
			#binding-cells = < 0x1 >;
		};
		macro_pause_for_release: macro_pause_for_release {
			compatible = "zmk,macro-pause-for-release";
			#binding-cells = < 0x0 >;
		};
		macro_param_1to1: macro_param_1to1 {
			compatible = "zmk,macro-param-1to1";
			#binding-cells = < 0x0 >;
		};
		macro_param_1to2: macro_param_1to2 {
			compatible = "zmk,macro-param-1to2";
			#binding-cells = < 0x0 >;
		};
		macro_param_2to1: macro_param_2to1 {
			compatible = "zmk,macro-param-2to1";
			#binding-cells = < 0x0 >;
		};
		macro_param_2to2: macro_param_2to2 {
			compatible = "zmk,macro-param-2to2";
			#binding-cells = < 0x0 >;
		};
		soft_off: z_so_off {
			compatible = "zmk,behavior-soft-off";
			#binding-cells = < 0x0 >;
			split-peripheral-off-on-press;
		};
		studio_unlock: studio_unlock {
			compatible = "zmk,behavior-studio-unlock";
			#binding-cells = < 0x0 >;
			display-name = "Studio Unlock";
		};
		mkp: mouse_key_press {
			compatible = "zmk,behavior-mouse-key-press";
			#binding-cells = < 0x1 >;
			display-name = "Mouse Key Press";
			phandle = < 0x26 >;
		};
		mmv: mouse_move {
			compatible = "zmk,behavior-input-two-axis";
			#binding-cells = < 0x1 >;
			x-input-code = < 0x0 >;
			y-input-code = < 0x1 >;
			time-to-max-speed-ms = < 0x12c >;
			acceleration-exponent = < 0x1 >;
			phandle = < 0x27 >;
		};
		msc: mouse_scroll {
			compatible = "zmk,behavior-input-two-axis";
			#binding-cells = < 0x1 >;
			x-input-code = < 0x6 >;
			y-input-code = < 0x8 >;
			time-to-max-speed-ms = < 0x12c >;
			acceleration-exponent = < 0x0 >;
			phandle = < 0x28 >;
		};
		hml: hml {
			compatible = "zmk,behavior-hold-tap";
			#binding-cells = < 0x2 >;
			bindings = < &kp >, < &kp >;
			flavor = "balanced";
			tapping-term-ms = < 0x118 >;
			quick-tap-ms = < 0xaf >;
			require-prior-idle-ms = < 0x96 >;
			hold-trigger-on-release;
			hold-trigger-key-positions = < 0x6 0x7 0x8 0x9 0xa 0xb 0x12 0x13 0x14 0x15 0x16 0x17 0x1e 0x1f 0x20 0x21 0x22 0x23 0x2a 0x2b 0x2c 0x2d 0x2e 0x2f 0x30 0x31 0x32 0x33 0x34 0x35 0x36 0x37 0x38 0x39 >;
			phandle = < 0x34 >;
		};
		hmr: hmr {
			compatible = "zmk,behavior-hold-tap";
			#binding-cells = < 0x2 >;
			bindings = < &kp >, < &kp >;
			flavor = "balanced";
			tapping-term-ms = < 0x118 >;
			quick-tap-ms = < 0xaf >;
			require-prior-idle-ms = < 0x96 >;
			hold-trigger-on-release;
			hold-trigger-key-positions = < 0x0 0x1 0x2 0x3 0x4 0x5 0xc 0xd 0xe 0xf 0x10 0x11 0x18 0x19 0x1a 0x1b 0x1c 0x1d 0x24 0x25 0x26 0x27 0x28 0x29 0x30 0x31 0x32 0x33 0x34 0x35 0x36 0x37 0x38 0x39 >;
			phandle = < 0x35 >;
		};
		combo_lbkt: combo_lbkt {
			compatible = "zmk,behavior-macro";
			#binding-cells = < 0x0 >;
			bindings = < &kp 0x7002f >;
			wait-ms = < 0x0 >;
			tap-ms = < 0x5 >;
			phandle = < 0x16 >;
		};
		combo_rbkt: combo_rbkt {
			compatible = "zmk,behavior-macro";
			#binding-cells = < 0x0 >;
			bindings = < &kp 0x70030 >;
			wait-ms = < 0x0 >;
			tap-ms = < 0x5 >;
			phandle = < 0x17 >;
		};
		combo_minus: combo_minus {
			compatible = "zmk,behavior-macro";
			#binding-cells = < 0x0 >;
			bindings = < &kp 0x7002d >;
			wait-ms = < 0x0 >;
			tap-ms = < 0x5 >;
			phandle = < 0x18 >;
		};
		combo_undscr: combo_undscr {
			compatible = "zmk,behavior-macro";
			#binding-cells = < 0x0 >;
			bindings = < &kp 0x207002d >;
			wait-ms = < 0x0 >;
			tap-ms = < 0x5 >;
			phandle = < 0x19 >;
		};
		combo_equal: combo_equal {
			compatible = "zmk,behavior-macro";
			#binding-cells = < 0x0 >;
			bindings = < &kp 0x7002e >;
			wait-ms = < 0x0 >;
			tap-ms = < 0x5 >;
			phandle = < 0x1a >;
		};
		combo_plus: combo_plus {
			compatible = "zmk,behavior-macro";
			#binding-cells = < 0x0 >;
			bindings = < &kp 0x207002e >;
			wait-ms = < 0x0 >;
			tap-ms = < 0x5 >;
			phandle = < 0x1b >;
		};
		combo_dquote: combo_dquote {
			compatible = "zmk,behavior-macro";
			#binding-cells = < 0x0 >;
			bindings = < &kp 0x2070034 >;
			wait-ms = < 0x0 >;
			tap-ms = < 0x5 >;
			phandle = < 0x1c >;
		};
		combo_squote: combo_squote {
			compatible = "zmk,behavior-macro";
			#binding-cells = < 0x0 >;
			bindings = < &kp 0x70034 >;
			wait-ms = < 0x0 >;
			tap-ms = < 0x5 >;
			phandle = < 0x1d >;
		};
		hm_combo_lbkt: hm_combo_lbkt {
			compatible = "zmk,behavior-hold-tap";
			#binding-cells = < 0x2 >;
			bindings = < &kp >, < &combo_lbkt >;
			flavor = "balanced";
			tapping-term-ms = < 0x118 >;
			quick-tap-ms = < 0xaf >;
			require-prior-idle-ms = < 0x96 >;
			hold-trigger-on-release;
			hold-trigger-key-positions = < 0x6 0x7 0x8 0x9 0xa 0xb 0x12 0x13 0x14 0x15 0x16 0x17 0x1e 0x1f 0x20 0x21 0x22 0x23 0x2a 0x2b 0x2c 0x2d 0x2e 0x2f 0x30 0x31 0x32 0x33 0x34 0x35 0x36 0x37 0x38 0x39 >;
			phandle = < 0x2a >;
		};
		hm_combo_rbkt: hm_combo_rbkt {
			compatible = "zmk,behavior-hold-tap";
			#binding-cells = < 0x2 >;
			bindings = < &kp >, < &combo_rbkt >;
			flavor = "balanced";
			tapping-term-ms = < 0x118 >;
			quick-tap-ms = < 0xaf >;
			require-prior-idle-ms = < 0x96 >;
			hold-trigger-on-release;
			hold-trigger-key-positions = < 0x0 0x1 0x2 0x3 0x4 0x5 0xc 0xd 0xe 0xf 0x10 0x11 0x18 0x19 0x1a 0x1b 0x1c 0x1d 0x24 0x25 0x26 0x27 0x28 0x29 0x30 0x31 0x32 0x33 0x34 0x35 0x36 0x37 0x38 0x39 >;
			phandle = < 0x2b >;
		};
		hm_combo_minus: hm_combo_minus {
			compatible = "zmk,behavior-hold-tap";
			#binding-cells = < 0x2 >;
			bindings = < &kp >, < &combo_minus >;
			flavor = "balanced";
			tapping-term-ms = < 0x118 >;
			quick-tap-ms = < 0xaf >;
			require-prior-idle-ms = < 0x96 >;
			hold-trigger-on-release;
			hold-trigger-key-positions = < 0x6 0x7 0x8 0x9 0xa 0xb 0x12 0x13 0x14 0x15 0x16 0x17 0x1e 0x1f 0x20 0x21 0x22 0x23 0x2a 0x2b 0x2c 0x2d 0x2e 0x2f 0x30 0x31 0x32 0x33 0x34 0x35 0x36 0x37 0x38 0x39 >;
			phandle = < 0x2c >;
		};
		hm_combo_undscr: hm_combo_undscr {
			compatible = "zmk,behavior-hold-tap";
			#binding-cells = < 0x2 >;
			bindings = < &kp >, < &combo_undscr >;
			flavor = "balanced";
			tapping-term-ms = < 0x118 >;
			quick-tap-ms = < 0xaf >;
			require-prior-idle-ms = < 0x96 >;
			hold-trigger-on-release;
			hold-trigger-key-positions = < 0x6 0x7 0x8 0x9 0xa 0xb 0x12 0x13 0x14 0x15 0x16 0x17 0x1e 0x1f 0x20 0x21 0x22 0x23 0x2a 0x2b 0x2c 0x2d 0x2e 0x2f 0x30 0x31 0x32 0x33 0x34 0x35 0x36 0x37 0x38 0x39 >;
			phandle = < 0x2d >;
		};
		hm_combo_equal: hm_combo_equal {
			compatible = "zmk,behavior-hold-tap";
			#binding-cells = < 0x2 >;
			bindings = < &kp >, < &combo_equal >;
			flavor = "balanced";
			tapping-term-ms = < 0x118 >;
			quick-tap-ms = < 0xaf >;
			require-prior-idle-ms = < 0x96 >;
			hold-trigger-on-release;
			hold-trigger-key-positions = < 0x0 0x1 0x2 0x3 0x4 0x5 0xc 0xd 0xe 0xf 0x10 0x11 0x18 0x19 0x1a 0x1b 0x1c 0x1d 0x24 0x25 0x26 0x27 0x28 0x29 0x30 0x31 0x32 0x33 0x34 0x35 0x36 0x37 0x38 0x39 >;
			phandle = < 0x2e >;
		};
		hm_combo_plus: hm_combo_plus {
			compatible = "zmk,behavior-hold-tap";
			#binding-cells = < 0x2 >;
			bindings = < &kp >, < &combo_plus >;
			flavor = "balanced";
			tapping-term-ms = < 0x118 >;
			quick-tap-ms = < 0xaf >;
			require-prior-idle-ms = < 0x96 >;
			hold-trigger-on-release;
			hold-trigger-key-positions = < 0x0 0x1 0x2 0x3 0x4 0x5 0xc 0xd 0xe 0xf 0x10 0x11 0x18 0x19 0x1a 0x1b 0x1c 0x1d 0x24 0x25 0x26 0x27 0x28 0x29 0x30 0x31 0x32 0x33 0x34 0x35 0x36 0x37 0x38 0x39 >;
			phandle = < 0x2f >;
		};
		hm_combo_dquote: hm_combo_dquote {
			compatible = "zmk,behavior-hold-tap";
			#binding-cells = < 0x2 >;
			bindings = < &kp >, < &combo_dquote >;
			flavor = "balanced";
			tapping-term-ms = < 0x118 >;
			quick-tap-ms = < 0xaf >;
			require-prior-idle-ms = < 0x96 >;
			hold-trigger-on-release;
			hold-trigger-key-positions = < 0x6 0x7 0x8 0x9 0xa 0xb 0x12 0x13 0x14 0x15 0x16 0x17 0x1e 0x1f 0x20 0x21 0x22 0x23 0x2a 0x2b 0x2c 0x2d 0x2e 0x2f 0x30 0x31 0x32 0x33 0x34 0x35 0x36 0x37 0x38 0x39 >;
			phandle = < 0x30 >;
		};
		hm_combo_squote: hm_combo_squote {
			compatible = "zmk,behavior-hold-tap";
			#binding-cells = < 0x2 >;
			bindings = < &kp >, < &combo_squote >;
			flavor = "balanced";
			tapping-term-ms = < 0x118 >;
			quick-tap-ms = < 0xaf >;
			require-prior-idle-ms = < 0x96 >;
			hold-trigger-on-release;
			hold-trigger-key-positions = < 0x0 0x1 0x2 0x3 0x4 0x5 0xc 0xd 0xe 0xf 0x10 0x11 0x18 0x19 0x1a 0x1b 0x1c 0x1d 0x24 0x25 0x26 0x27 0x28 0x29 0x30 0x31 0x32 0x33 0x34 0x35 0x36 0x37 0x38 0x39 >;
			phandle = < 0x31 >;
		};
		mt_home: mt_home {
			compatible = "zmk,behavior-hold-tap";
			#binding-cells = < 0x2 >;
			bindings = < &masked_home >, < &kp >;
			flavor = "tap-preferred";
			tapping-term-ms = < 0xdc >;
			quick-tap-ms = < 0xdc >;
			hold-trigger-key-positions = < 0x0 >;
			phandle = < 0x3b >;
		};
		mt_end: mt_end {
			compatible = "zmk,behavior-hold-tap";
			#binding-cells = < 0x2 >;
			bindings = < &masked_end >, < &kp >;
			flavor = "tap-preferred";
			tapping-term-ms = < 0xdc >;
			quick-tap-ms = < 0xdc >;
			hold-trigger-key-positions = < 0x0 >;
			phandle = < 0x3c >;
		};
		masked_home: masked_home {
			compatible = "zmk,behavior-mod-morph";
			#binding-cells = < 0x0 >;
			bindings = < &kp 0x7004a >, < &kp 0x7004a >;
			mods = < 0x1 >;
			phandle = < 0x1e >;
		};
		masked_end: masked_end {
			compatible = "zmk,behavior-mod-morph";
			#binding-cells = < 0x0 >;
			bindings = < &kp 0x7004d >, < &kp 0x7004d >;
			mods = < 0x1 >;
			phandle = < 0x1f >;
		};
		swapper: swapper {
			compatible = "zmk,behavior-tri-state";
			#binding-cells = < 0x0 >;
			bindings = < &kt 0x700e2 >, < &kp 0x7002b >, < &kt 0x700e2 >;
			ignored-key-positions = < 0x14 0x20 0x1f 0x21 >;
			phandle = < 0x39 >;
		};
		comma_morph: comma_morph {
			compatible = "zmk,behavior-mod-morph";
			#binding-cells = < 0x0 >;
			mods = < 0x22 >;
			bindings = < &kp 0x70036 >, < &comma_inner_morph >;
		};
		comma_inner_morph: comma_inner_morph {
			compatible = "zmk,behavior-mod-morph";
			#binding-cells = < 0x0 >;
			mods = < 0x11 >;
			bindings = < &kp 0x70033 >, < &kp 0x2070036 >;
			phandle = < 0x21 >;
		};
		dot_morph: dot_morph {
			compatible = "zmk,behavior-mod-morph";
			#binding-cells = < 0x0 >;
			mods = < 0x22 >;
			bindings = < &kp 0x70037 >, < &dot_inner_morph >;
		};
		dot_inner_morph: dot_inner_morph {
			compatible = "zmk,behavior-mod-morph";
			#binding-cells = < 0x0 >;
			mods = < 0x11 >;
			bindings = < &kp 0x2070033 >, < &kp 0x2070037 >;
			phandle = < 0x22 >;
		};
		qexcl: qexcl {
			compatible = "zmk,behavior-mod-morph";
			#binding-cells = < 0x0 >;
			mods = < 0x22 >;
			bindings = < &kp 0x2070038 >, < &kp 0x207001e >;
		};
		lpar_lt: lpar_lt {
			compatible = "zmk,behavior-mod-morph";
			#binding-cells = < 0x0 >;
			mods = < 0x22 >;
			bindings = < &kp 0x2070026 >, < &kp 0x2070036 >;
		};
		rpar_gt: rpar_gt {
			compatible = "zmk,behavior-mod-morph";
			#binding-cells = < 0x0 >;
			mods = < 0x22 >;
			bindings = < &kp 0x2070027 >, < &kp 0x2070037 >;
		};
		lt_spc: lt_spc {
			compatible = "zmk,behavior-hold-tap";
			#binding-cells = < 0x2 >;
			bindings = < &mo >, < &spc_morph >;
			flavor = "balanced";
			tapping-term-ms = < 0xc8 >;
			quick-tap-ms = < 0xaf >;
		};
		spc_morph: spc_morph {
			compatible = "zmk,behavior-mod-morph";
			#binding-cells = < 0x0 >;
			mods = < 0x22 >;
			bindings = < &kp 0x7002c >, < &dot_spc >;
			phandle = < 0x23 >;
		};
		dot_spc: dot_spc {
			compatible = "zmk,behavior-macro";
			#binding-cells = < 0x0 >;
			bindings = < &kp 0x70037 &kp 0x7002c &sk 0x700e1 >;
			wait-ms = < 0x0 >;
			tap-ms = < 0x5 >;
			phandle = < 0x24 >;
		};
		bs_del: bs_del {
			compatible = "zmk,behavior-mod-morph";
			#binding-cells = < 0x0 >;
			bindings = < &kp 0x7002a >, < &kp 0x7004c >;
			mods = < 0x22 >;
			keep-mods = < 0x20 >;
		};
		copy_cut: copy_cut {
			compatible = "zmk,behavior-tap-dance";
			#binding-cells = < 0x0 >;
			bindings = < &kp 0x1070049 >, < &kp 0x107001b >;
			tapping-term-ms = < 0xc8 >;
		};
		ltf: ltf {
			compatible = "zmk,behavior-hold-tap";
			#binding-cells = < 0x2 >;
			flavor = "hold-preferred";
			tapping-term-ms = < 0xc8 >;
			bindings = < &mo >, < &kp >;
			phandle = < 0x37 >;
		};
		pmt: pmt {
			compatible = "zmk,behavior-hold-tap";
			#binding-cells = < 0x2 >;
			flavor = "balanced";
			tapping-term-ms = < 0xc8 >;
			quick-tap-ms = < 0x78 >;
			require-prior-idle-ms = < 0x78 >;
			bindings = < &kp >, < &kp >;
			phandle = < 0x33 >;
		};
	};
	mkp_input_listener: mkp_input_listener {
		compatible = "zmk,input-listener";
		device = < &mkp >;
	};
	mmv_input_listener: mmv_input_listener {
		compatible = "zmk,input-listener";
		device = < &mmv >;
	};
	msc_input_listener: msc_input_listener {
		compatible = "zmk,input-listener";
		device = < &msc >;
	};
	combos {
		compatible = "zmk,combos";
		combo_cut {
			timeout-ms = < 0x1e >;
			bindings = < &kp 0x107001b >;
			key-positions = < 0x26 0x28 >;
			layers = < 0x0 0x1 >;
			require-prior-idle-ms = < 0x96 >;
		};
		combo_copy {
			timeout-ms = < 0x1e >;
			bindings = < &kp 0x1070049 >;
			key-positions = < 0x26 0x27 >;
			layers = < 0x0 0x1 >;
			require-prior-idle-ms = < 0x96 >;
		};
		combo_paste {
			timeout-ms = < 0x1e >;
			bindings = < &kp 0x2070049 >;
			key-positions = < 0x27 0x28 >;
			layers = < 0x0 0x1 >;
			require-prior-idle-ms = < 0x96 >;
		};
		combo_caps_word {
			timeout-ms = < 0x1e >;
			bindings = < &caps_word >;
			key-positions = < 0x1b 0x20 >;
			layers = < 0x0 0x1 >;
			require-prior-idle-ms = < 0x96 >;
		};
		combo_bracket {
			timeout-ms = < 0x1e >;
			bindings = < &caps_word >;
			key-positions = < 0x1b 0x20 >;
			layers = < 0x0 0x1 >;
			require-prior-idle-ms = < 0x96 >;
		};
		combo_lpar {
			timeout-ms = < 0x1e >;
			bindings = < &kp 0x2070026 >;
			key-positions = < 0x10 0x11 >;
			layers = < 0x0 0x1 >;
			require-prior-idle-ms = < 0x96 >;
		};
		combo_lbkt {
			timeout-ms = < 0x1e >;
			bindings = < &hm_combo_lbkt 0x700e1 0x0 >;
			key-positions = < 0x1c 0x1d >;
			layers = < 0x0 0x1 >;
			require-prior-idle-ms = < 0x96 >;
		};
		combo_lbrc {
			timeout-ms = < 0x1e >;
			bindings = < &kp 0x207002f >;
			key-positions = < 0x28 0x29 >;
			layers = < 0x0 0x1 >;
			require-prior-idle-ms = < 0x96 >;
		};
		combo_rpar {
			timeout-ms = < 0x1e >;
			bindings = < &kp 0x2070027 >;
			key-positions = < 0x12 0x13 >;
			layers = < 0x0 0x1 >;
			require-prior-idle-ms = < 0x96 >;
		};
		combo_rbkt {
			timeout-ms = < 0x1e >;
			bindings = < &hm_combo_rbkt 0x700e1 0x0 >;
			key-positions = < 0x1e 0x1f >;
			layers = < 0x0 0x1 >;
			require-prior-idle-ms = < 0x96 >;
		};
		combo_rbrc {
			timeout-ms = < 0x1e >;
			bindings = < &kp 0x2070030 >;
			key-positions = < 0x2a 0x2b >;
			layers = < 0x0 0x1 >;
			require-prior-idle-ms = < 0x96 >;
		};
		combo_ru_b {
			timeout-ms = < 0x1e >;
			bindings = < &kp 0x70059 >;
			key-positions = < 0x2b 0x2c >;
			layers = < 0x0 >;
			require-prior-idle-ms = < 0x96 >;
		};
		combo_ru_yu {
			timeout-ms = < 0x1e >;
			bindings = < &kp 0x70038 >;
			key-positions = < 0x2c 0x2d >;
			layers = < 0x0 >;
			require-prior-idle-ms = < 0x96 >;
		};
		combo_minus {
			timeout-ms = < 0x1e >;
			bindings = < &hm_combo_minus 0x20700e0 0x0 >;
			key-positions = < 0x1b 0x1c >;
			layers = < 0x0 >;
			require-prior-idle-ms = < 0x96 >;
		};
		combo_undscr {
			timeout-ms = < 0x1e >;
			bindings = < &hm_combo_undscr 0x10700e2 0x0 >;
			key-positions = < 0x1a 0x1b >;
			layers = < 0x0 >;
			require-prior-idle-ms = < 0x96 >;
		};
		combo_equal {
			timeout-ms = < 0x1e >;
			bindings = < &hm_combo_equal 0x20700e0 0x0 >;
			key-positions = < 0x1f 0x20 >;
			layers = < 0x0 >;
			require-prior-idle-ms = < 0x96 >;
		};
		combo_plus {
			timeout-ms = < 0x1e >;
			bindings = < &hm_combo_plus 0x10700e2 0x0 >;
			key-positions = < 0x20 0x21 >;
			layers = < 0x0 >;
			require-prior-idle-ms = < 0x96 >;
		};
		combo_dollar {
			timeout-ms = < 0x1e >;
			bindings = < &kp 0x2070021 >;
			key-positions = < 0xf 0x10 >;
			layers = < 0x0 >;
			require-prior-idle-ms = < 0x96 >;
		};
		combo_exclamation {
			timeout-ms = < 0x1e >;
			bindings = < &kp 0x207001e >;
			key-positions = < 0xe 0xf >;
			layers = < 0x0 >;
			require-prior-idle-ms = < 0x96 >;
		};
		combo_question {
			timeout-ms = < 0x1e >;
			bindings = < &kp 0x2070024 >;
			key-positions = < 0x13 0x14 >;
			layers = < 0x0 >;
			require-prior-idle-ms = < 0x96 >;
		};
		combo_dquote {
			timeout-ms = < 0x1e >;
			bindings = < &hm_combo_dquote 0x20700e2 0x0 >;
			key-positions = < 0x1a 0x1c >;
			layers = < 0x0 >;
			require-prior-idle-ms = < 0x96 >;
		};
		combo_squote {
			timeout-ms = < 0x1e >;
			bindings = < &hm_combo_squote 0x20700e2 0x0 >;
			key-positions = < 0x1f 0x21 >;
			layers = < 0x0 >;
			require-prior-idle-ms = < 0x96 >;
		};
	};
	keymap {
		compatible = "zmk,keymap";
		layer_Base {
			display-name = "Base";
			bindings = < &kp 0x70029 &kp 0x7001e &kp 0x7001f &kp 0x70020 &kp 0x70021 &lt 0x3 0x70022 &kp 0x70023 &kp 0x70024 &kp 0x70025 &kp 0x70026 &kp 0x70027 &kp 0x70035 &pmt 0x700e3 0x7002b &kp 0x70014 &kp 0x7001a &kp 0x70008 &kp 0x70015 &kp 0x70017 &kp 0x7001c &kp 0x70018 &kp 0x7000c &kp 0x70012 &kp 0x70013 &pmt 0x700e3 0x7002f &kp 0x700e1 &hml 0x700e3 0x70004 &hml 0x700e2 0x70016 &hml 0x700e0 0x70007 &hml 0x700e1 0x70009 &kp 0x7000a &kp 0x7000b &hmr 0x700e1 0x7000d &hmr 0x700e0 0x7000e &hmr 0x700e2 0x7000f &hmr 0x700e3 0x70033 &pmt 0x700e1 0x70034 &kp 0x700e0 &kp 0x7001d &kp 0x7001b &kp 0x70006 &kp 0x70019 &kp 0x70005 &kp 0x70011 &kp 0x70010 &kp 0x70036 &kp 0x70037 &kp 0x70038 &kp 0x700e0 &none &none &kp 0x700e2 &ltf 0x1 0x7002c &kp 0x70028 &lt 0x2 0x7002a &lt 0x2 0x7004c &mo 0x2 &none &kp 0x700e6 >;
		};
		layer_Nav {
			display-name = "Nav";
			bindings = < &trans &kp 0x7003a &kp 0x7003b &kp 0x7003c &kp 0x7003d &kp 0x7003e &kp 0x7003f &kp 0x70040 &kp 0x70041 &kp 0x70042 &kp 0x70043 &trans &swapper &trans &trans &trans &kp 0x407003a &trans &kp 0x7004b &kp 0x7004a &mt 0x107004a 0x70052 &kp 0x7004d &trans &trans &trans &trans &trans &trans &trans &trans &kp 0x7004e &mt_home 0x0 0x70050 &mt 0x107004d 0x70051 &mt_end 0x0 0x7004f &trans &trans &trans &kp 0x3070044 &kp 0x3070045 &trans &trans &kp 0x40700e1 &kp 0x7002d &kp 0x7002e &trans &trans &trans &trans &trans &trans &trans &trans &trans &mt 0x107002a 0x7002a &mt 0x107004c 0x7004c &trans &trans &kp 0x70031 >;
		};
		layer_Fn {
			display-name = "Fn";
			bindings = < &trans &trans &trans &trans &trans &trans &trans &trans &trans &trans &trans &trans &trans &trans &trans &trans &trans &trans &kp 0x70046 &trans &trans &trans &trans &trans &trans &trans &trans &trans &trans &trans &kp 0x70049 &trans &trans &trans &trans &trans &trans &trans &trans &trans &trans &trans &trans &kp 0xc00e2 &kp 0xc00ea &kp 0xc00e9 &kp 0xc00b5 &trans &trans &trans &trans &trans &trans &trans &trans &trans &trans &trans >;
		};
	};
};
